# M480_v1 register map
File version: 1.0
Registers are 32-bit, read-write, reset 0x0 unless marked. A register's access mark holds for its fields unless they carry their own. Offsets are from the block's base; [hi:lo] are bit positions; lines under a group give offsets from that group; {n}, {i} and the like mark numbered series; 'fields as' and 'values as' point back to an identical list.

## EPWM0 — EPWM Register Map
Base 0x40058000
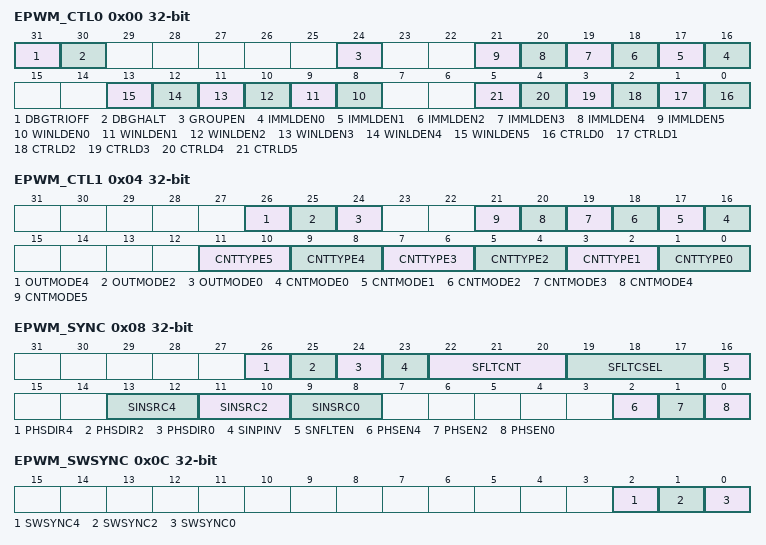
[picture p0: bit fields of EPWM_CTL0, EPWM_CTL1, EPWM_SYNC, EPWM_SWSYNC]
0x00 EPWM_CTL0 — EPWM Control Register 0
  [31] DBGTRIOFF — ICE Debug Mode Acknowledge Disable Bit (Write Protect). EPWM pin will keep output no matter ICE debug mode acknowledged or not. Note: This bit is write protected. Refer to SYS_REGLCTL register.
    0=ICE debug mode acknowledgement effects EPWM output; 1=ICE debug mode acknowledgement disabled
  [30] DBGHALT — ICE Debug Mode Counter Halt (Write Protect). If counter halt is enabled, EPWM all counters will keep current value until exit ICE debug mode. Note: This bit is write protected. Refer to SYS_REGLCTL register.
    0=ICE debug mode counter halt Disabled; 1=ICE debug mode counter halt Enabled
  [24] GROUPEN — Group Function Enable Bit
    0=The output waveform of each EPWM channel are independent; 1=Unify the EPWM_CH2 and EPWM_CH4 to output the same waveform as EPWM_CH0 and unify the EPWM_CH3 and EPWM_CH5 to output the same waveform as EPWM_CH1
  [n+16] IMMLDEN{n} (n=0..5) — Immediately Load Enable Bits. Note: If IMMLDENn is enabled, WINLDENn and CTRLDn will be invalid.
    0=PERIOD will load to PBUF at the end point of each period. CMP will load to CMPBUF at the end point or center point of each period by setting CTRLD bit; 1=PERIOD/CMP will load to PBUF and CMPBUF immediately when software update PERIOD/CMP
  [n+8] WINLDEN{n} (n=0..5) — Window Load Enable Bits
    0=PERIOD will load to PBUF at the end point of each period. CMP will load to CMPBUF at the end point or center point of each period by setting CTRLD bit; 1=PERIOD will load to PBUF at the end point of each period. CMP will load to CMPBUF at the end point of each period when valid reload window is set. The valid reload window is set by software write 1 to EPWM_LOAD register and cleared by hardware after load success
  [n] CTRLD{n} (n=0..5) — Center Re-load. In up-down counter type, PERIOD will load to PBUF at the end point of each period. CMP will load to CMPBUF at the center point of a period.
0x04 EPWM_CTL1 — EPWM Control Register 1
  [26] OUTMODE4 — EPWM Output Mode. Each bit n controls the output mode of corresponding EPWM channel n. Note: When operating in group function, these bits must all set to the same mode.
    0=EPWM independent mode; 1=EPWM complementary mode
  [25] OUTMODE2 — EPWM Output Mode. Each bit n controls the output mode of corresponding EPWM channel n. Note: When operating in group function, these bits must all set to the same mode.
    0=EPWM independent mode; 1=EPWM complementary mode
  [24] OUTMODE0 — EPWM Output Mode. Each bit n controls the output mode of corresponding EPWM channel n. Note: When operating in group function, these bits must all set to the same mode.
    0=EPWM independent mode; 1=EPWM complementary mode
  [n+16] CNTMODE{n} (n=0..5) — EPWM Counter Mode
    0=Auto-reload mode; 1=One-shot mode
  [2n+1:2n] CNTTYPE{n} (n=0..5) — EPWM Counter Behavior Type
    0=Up counter type (supported in capture mode); 1=Down count type (supported in capture mode); 2=Up-down counter type
0x08 EPWM_SYNC — EPWM Synchronization Register
  [26] PHSDIR4 — EPWM Phase Direction Control
    0=Control EPWM counter count decrement after synchronizing; 1=Control EPWM counter count increment after synchronizing
  [25] PHSDIR2 — EPWM Phase Direction Control
    values as PHSDIR4
  [24] PHSDIR0 — EPWM Phase Direction Control
    values as PHSDIR4
  [23] SINPINV — SYNC Input Pin Inverse
    0=The state of pin SYNC is passed to the negative edge detector; 1=The inversed state of pin SYNC is passed to the negative edge detector
  [22:20] SFLTCNT — SYNC Edge Detector Filter Count. The register bits control the counter number of edge detector.
  [19:17] SFLTCSEL — SYNC Edge Detector Filter Clock Selection
    0=Filter clock = HCLK; 1=Filter clock = HCLK/2; 2=Filter clock = HCLK/4; 3=Filter clock = HCLK/8; 4=Filter clock = HCLK/16; 5=Filter clock = HCLK/32; 6=Filter clock = HCLK/64; 7=Filter clock = HCLK/128
  [16] SNFLTEN — EPWM0_SYNC_IN Noise Filter Enable Bits
    0=Noise filter of input pin EPWM0_SYNC_IN Disabled; 1=Noise filter of input pin EPWM0_SYNC_IN Enabled
  [13:12] SINSRC4 — EPWM0_SYNC_IN Source Selection
    0=Synchronize source from SYNC_IN or SWSYNC; 1=Counter equal to 0; 2=Counter equal to EPWM_CMPDATm, m denotes 1, 3, 5; 3=SYNC_OUT will not be generated
  [11:10] SINSRC2 — EPWM0_SYNC_IN Source Selection
    values as SINSRC4
  [9:8] SINSRC0 — EPWM0_SYNC_IN Source Selection
    values as SINSRC4
  [2] PHSEN4 — SYNC Phase Enable Bits
    0=EPWM counter disable to load PHS value; 1=EPWM counter enable to load PHS value
  [1] PHSEN2 — SYNC Phase Enable Bits
    values as PHSEN4
  [0] PHSEN0 — SYNC Phase Enable Bits
    values as PHSEN4
0x0C EPWM_SWSYNC — EPWM Software Control Synchronization Register
  [2] SWSYNC4 — Software SYNC Function. When SINSRCn (EPWM_SYNC[13:8]) is selected to 0, SYNC_OUT source comes from SYNC_IN or this bit.
  [1] SWSYNC2 — Software SYNC Function. When SINSRCn (EPWM_SYNC[13:8]) is selected to 0, SYNC_OUT source comes from SYNC_IN or this bit.
  [0] SWSYNC0 — Software SYNC Function. When SINSRCn (EPWM_SYNC[13:8]) is selected to 0, SYNC_OUT source comes from SYNC_IN or this bit.
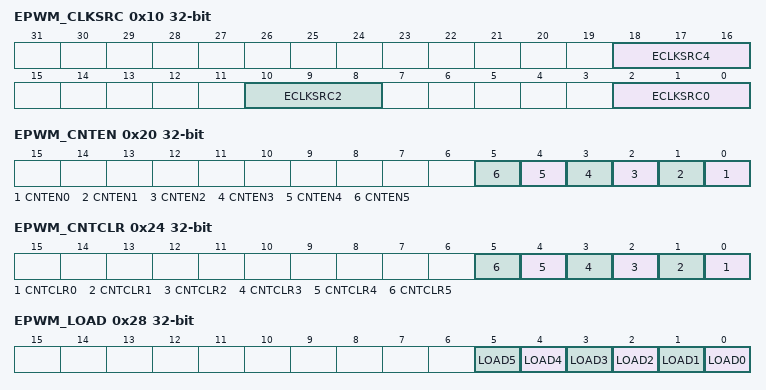
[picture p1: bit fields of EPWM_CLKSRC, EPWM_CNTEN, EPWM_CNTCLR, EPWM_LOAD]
0x10 EPWM_CLKSRC — EPWM Clock Source Register
  [all] fields
    0=EPWMx_CLK, x denotes 0 or 1; {v}=TIMER{v-1} overflow (v=1..4)
  [18:16] ECLKSRC4 — EPWM_CH45 External Clock Source Select
  [10:8] ECLKSRC2 — EPWM_CH23 External Clock Source Select
  [2:0] ECLKSRC0 — EPWM_CH01 External Clock Source Select
0x14 EPWM_CLKPSC0_1 — EPWM Clock Prescale Register 0/1
  [11:0] CLKPSC — EPWM Counter Clock Prescale. The clock of EPWM counter is decided by clock prescaler. Each EPWM pair share one EPWM counter clock prescaler. The clock of EPWM counter is divided by (CLKPSC+ 1).
0x18 EPWM_CLKPSC2_3 — EPWM Clock Prescale Register 2/3
  fields as EPWM_CLKPSC0_1
0x1C EPWM_CLKPSC4_5 — EPWM Clock Prescale Register 4/5
  fields as EPWM_CLKPSC0_1
0x20 EPWM_CNTEN — EPWM Counter Enable Register
  [all] fields
    0=EPWM Counter and clock prescaler stop running; 1=EPWM Counter and clock prescaler start running
  [n] CNTEN{n} (n=0..5) — EPWM Counter Enable Bits
0x24 EPWM_CNTCLR — EPWM Clear Counter Register
  [all] fields
    0=No effect; 1=Clear 16-bit EPWM counter to 0000H
  [n] CNTCLR{n} (n=0..5) — Clear EPWM Counter Control Bit. It is automatically cleared by hardware. Each bit n controls the corresponding EPWM channel n.
0x28 EPWM_LOAD
  [all] fields
    0=No effect. No load window is set; 1=Set load window of window loading mode. Load window is set
  [n] LOAD{n} (n=0..5) — Re-load EPWM Comparator Register (EPWM_CMPDATn) Control Bit. This bit is software write, hardware clear when current EPWM period end. Write Operation:
{0x30+4i} EPWM_PERIOD{i} (i=0..5) — EPWM Period Register {i}
  [15:0] PERIOD — EPWM Period Register. Up-Count mode: In this mode, EPWM counter counts from 0 to PERIOD, and restarts from 0.
{0x50+4i} EPWM_CMPDAT{i} (i=0..5) — EPWM Comparator Register {i}
  [15:0] CMP — EPWM Comparator Register. CMP is used to compare with CNT (EPWM_CNTn[15:0]) bits to generate EPWM waveform, interrupt and trigger EADC/DAC. In complementary mode, EPWM_CMPDAT0, EPWM_CMPDAT 2, EPWM_CMPDAT4 denote as first compared point, and EPWM_CMPDAT1, EPWM_CMPDAT3, EPWM_CMPDAT5 denote as second compared point for the corresponding 3 complementary pairs EPWM_CH0 and EPWM_CH1, EPWM_CH2 and EPWM_CH3, EPWM_CH4 and EPWM_CH5.
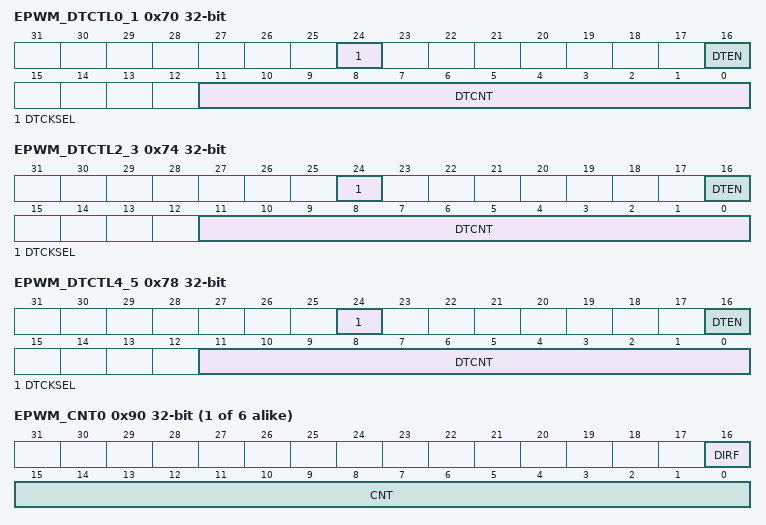
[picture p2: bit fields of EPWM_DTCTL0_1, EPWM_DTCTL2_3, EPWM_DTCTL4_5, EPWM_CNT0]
0x70 EPWM_DTCTL0_1 — EPWM Dead-time Control Register 0/1
  [24] DTCKSEL — Dead-time Clock Select (Write Protect). Note: This bit is write protected. Refer to REGWRPROT register.
    0=Dead-time clock source from EPWM_CLK; 1=Dead-time clock source from prescaler output
  [16] DTEN — Enable Dead-time Insertion for EPWM Pair (EPWM_CH0, EPWM_CH1) (EPWM_CH2, EPWM_CH3) (EPWM_CH4, EPWM_CH5) (Write Protect). Dead-time insertion is only active when this pair of complementary EPWM is enabled. If dead- time insertion is inactive, the outputs of pin pair are complementary without any delay. Note: This bit is write protected. Refer to SYS_REGLCTL register.
    0=Dead-time insertion Disabled on the pin pair; 1=Dead-time insertion Enabled on the pin pair
  [11:0] DTCNT — Dead-time Counter (Write Protect). The dead-time can be calculated from the following formula: Note: This bit is write protected. Refer to SYS_REGLCTL register.
0x74 EPWM_DTCTL2_3 — EPWM Dead-time Control Register 2/3
  fields as EPWM_DTCTL0_1
0x78 EPWM_DTCTL4_5 — EPWM Dead-time Control Register 4/5
  fields as EPWM_DTCTL0_1
0x80 EPWM_PHS0_1 — EPWM Counter Phase Register 0/1
  [15:0] PHS — EPWM Synchronous Start Phase Bits. PHS determines the EPWM synchronous start phase value. These bits only use in synchronous function.
0x84 EPWM_PHS2_3 — EPWM Counter Phase Register 2/3
  fields as EPWM_PHS0_1
0x88 EPWM_PHS4_5 — EPWM Counter Phase Register 4/5
  fields as EPWM_PHS0_1
{0x90+4i} EPWM_CNT{i} ro (i=0..5) — EPWM Counter Register {i}
  [16] DIRF — EPWM Direction Indicator Flag (Read Only)
    0=Counter is counting down; 1=Counter is counting up
  [15:0] CNT — EPWM Data Register (Read Only). User can monitor CNT to know the current value in 16-bit period counter.
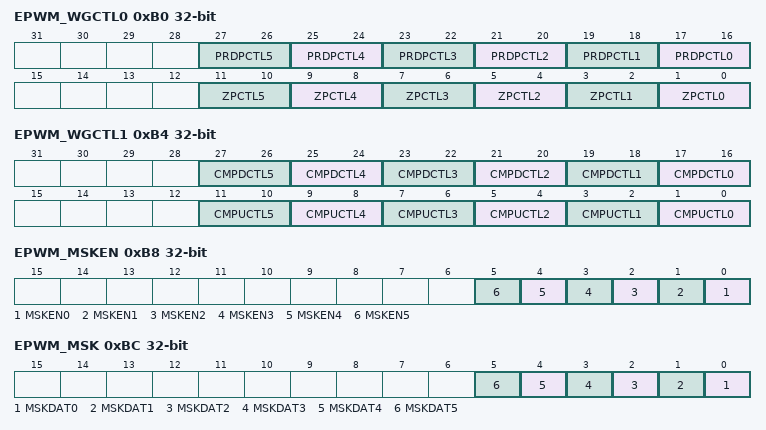
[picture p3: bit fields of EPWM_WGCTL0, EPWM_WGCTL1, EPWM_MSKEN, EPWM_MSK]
0xB0 EPWM_WGCTL0 — EPWM Generation Register 0
  [2n+17:2n+16] PRDPCTL{n} (n=0..5) — EPWM Period (Center) Point Control. EPWM can control output level when EPWM counter counts to (PERIODn+1). Note: This bit is center point control when EPWM counter operating in up-down counter type.
    0=Do nothing; 1=EPWM period (center) point output Low; 2=EPWM period (center) point output High; 3=EPWM period (center) point output Toggle
  [2n+1:2n] ZPCTL{n} (n=0..5) — EPWM Zero Point Control. EPWM can control output level when EPWM counter counts to 0.
    0=Do nothing; 1=EPWM zero point output Low; 2=EPWM zero point output High; 3=EPWM zero point output Toggle
0xB4 EPWM_WGCTL1 — EPWM Generation Register 1
  [2n+17:2n+16] CMPDCTL{n} (n=0..5) — EPWM Compare Down Point Control. EPWM can control output level when EPWM counter counts down to CMP. Note: In complementary mode, CMPDCTL1, 3, 5 is used as another CMPDCTL for channel 0, 2, 4.
    0=Do nothing; 1=EPWM compare down point output Low; 2=EPWM compare down point output High; 3=EPWM compare down point output Toggle
  [2n+1:2n] CMPUCTL{n} (n=0..5) — EPWM Compare Up Point Control. EPWM can control output level when EPWM counter counts up to CMP. Note: In complementary mode, CMPUCTL1, 3, 5 is used as another CMPUCTL for channel 0, 2, 4.
    0=Do nothing; 1=EPWM compare up point output Low; 2=EPWM compare up point output High; 3=EPWM compare up point output Toggle
0xB8 EPWM_MSKEN — EPWM Mask Enable Register
  [all] fields
    0=EPWM output signal is non-masked; 1=EPWM output signal is masked and output MSKDATn data
  [n] MSKEN{n} (n=0..5) — EPWM Mask Enable Bits. The EPWM output signal will be masked when this bit is enabled. The corresponding EPWM channel n will output MSKDATn (EPWM_MSK[5:0]) data.
0xBC EPWM_MSK — EPWM Mask Data Register
  [all] fields
    0=Output logic low to EPWM channel n; 1=Output logic high to EPWM channel n
  [n] MSKDAT{n} (n=0..5) — EPWM Mask Data Bit. This data bit control the state of EPWMn output pin, if corresponding mask function is enabled.
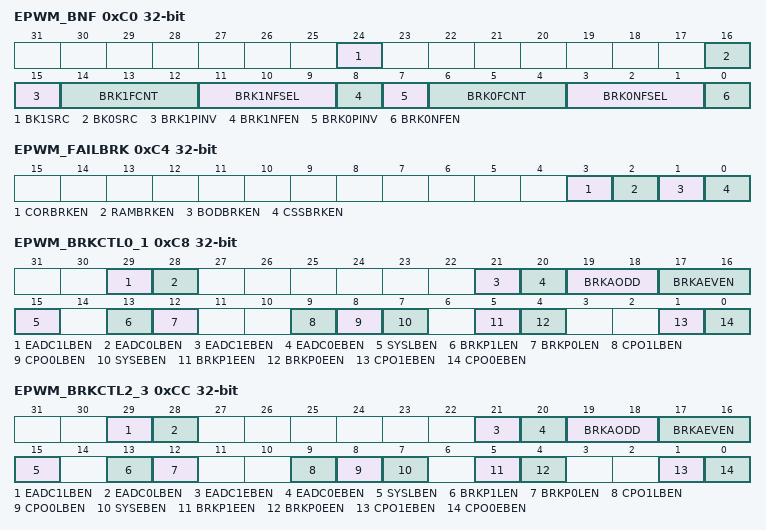
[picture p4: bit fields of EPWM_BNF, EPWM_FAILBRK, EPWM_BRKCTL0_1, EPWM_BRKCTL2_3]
0xC0 EPWM_BNF — EPWM Brake Noise Filter Register
  [24] BK1SRC — Brake 1 Pin Source Select. For EPWM0 setting:
    0=Brake 1 pin source come from EPWM0_BRAKE1. Brake 1 pin source come from EPWM1_BRAKE1; 1=Brake 1 pin source come from EPWM1_BRAKE1. Brake 1 pin source come from EPWM0_BRAKE1
  [16] BK0SRC — Brake 0 Pin Source Select. For EPWM0 setting:
    0=Brake 0 pin source come from EPWM0_BRAKE0. Brake 0 pin source come from EPWM1_BRAKE0; 1=Brake 0 pin source come from EPWM1_BRAKE0. Brake 0 pin source come from EPWM0_BRAKE0
  [15] BRK1PINV — Brake 1 Pin Inverse
    0=brake pin event will be detected if EPWMx_BRAKE1 pin status transfer from low to high in edge-detect, or pin status is high in level-detect; 1=brake pin event will be detected if EPWMx_BRAKE1 pin status transfer from high to low in edge-detect, or pin status is low in level-detect
  [14:12] BRK1FCNT — Brake 1 Edge Detector Filter Count. The register bits control the Brake1 filter counter to count from 0 to BRK1FCNT.
  [11:9] BRK1NFSEL — Brake 1 Edge Detector Filter Clock Selection
    values as EPWM_SYNC.SFLTCSEL
  [8] BRK1NFEN — EPWM Brake 1 Noise Filter Enable Bit
    0=Noise filter of EPWM Brake 1 Disabled; 1=Noise filter of EPWM Brake 1 Enabled
  [7] BRK0PINV — Brake 0 Pin Inverse
    0=brake pin event will be detected if EPWMx_BRAKE0 pin status transfer from low to high in edge-detect, or pin status is high in level-detect; 1=brake pin event will be detected if EPWMx_BRAKE0 pin status transfer from high to low in edge-detect, or pin status is low in level-detect
  [6:4] BRK0FCNT — Brake 0 Edge Detector Filter Count. The register bits control the Brake0 filter counter to count from 0 to BRK0FCNT.
  [3:1] BRK0NFSEL — Brake 0 Edge Detector Filter Clock Selection
    values as EPWM_SYNC.SFLTCSEL
  [0] BRK0NFEN — EPWM Brake 0 Noise Filter Enable Bit
    0=Noise filter of EPWM Brake 0 Disabled; 1=Noise filter of EPWM Brake 0 Enabled
0xC4 EPWM_FAILBRK — EPWM System Fail Brake Control Register
  [3] CORBRKEN — Core Lockup Detection Trigger EPWM Brake Function 0 Enable Bit
    0=Brake Function triggered by Core lockup detection Disabled; 1=Brake Function triggered by Core lockup detection Enabled
  [2] RAMBRKEN — SRAM Parity Error Detection Trigger EPWM Brake Function 0 Enable Bit
    0=Brake Function triggered by SRAM parity error detection Disabled; 1=Brake Function triggered by SRAM parity error detection Enabled
  [1] BODBRKEN — Brown-out Detection Trigger EPWM Brake Function 0 Enable Bit
    0=Brake Function triggered by BOD Disabled; 1=Brake Function triggered by BOD Enabled
  [0] CSSBRKEN — Clock Security System Detection Trigger EPWM Brake Function 0 Enable Bit
    0=Brake Function triggered by CSS detection Disabled; 1=Brake Function triggered by CSS detection Enabled
0xC8 EPWM_BRKCTL0_1 — EPWM Brake Edge Detect Control Register 0/1
  [29] EADC1LBEN — Enable EADC1 Result Monitor (EADC1RM) As Level-detect Brake Source (Write Protect). Note: This bit is write protected. Refer to SYS_REGLCTL register.
    0=EADC1RM as level-detect brake source Disabled; 1=EADC1RM as level-detect brake source Enabled
  [28] EADC0LBEN — Enable EADC0 Result Monitor (EADC0RM) As Level-detect Brake Source (Write Protect). Note: This bit is write protected. Refer to SYS_REGLCTL register.
    0=EADC0RM as level-detect brake source Disabled; 1=EADC0RM as level-detect brake source Enabled
  [21] EADC1EBEN — Enable EADC1 Result Monitor (EADC1RM) As Edge-detect Brake Source (Write Protect). Note: This bit is write protected. Refer to SYS_REGLCTL register.
    0=EADC1RM as edge-detect brake source Disabled; 1=EADC1RM as edge-detect brake source Enabled
  [20] EADC0EBEN — Enable EADC0 Result Monitor (EADC0RM) As Edge-detect Brake Source (Write Protect). Note: This bit is write protected. Refer to SYS_REGLCTL register.
    0=EADC0RM as edge-detect brake source Disabled; 1=EADC0RM as edge-detect brake source Enabled
  [19:18] BRKAODD — EPWM Brake Action Select for Odd Channel (Write Protect). Note: This bit is write protected. Refer to SYS_REGLCTL register.
    0=EPWMx brake event will not affect odd channels output; 1=EPWM odd channel output tri-state when EPWMx brake event happened; 2=EPWM odd channel output low level when EPWMx brake event happened; 3=EPWM odd channel output high level when EPWMx brake event happened
  [17:16] BRKAEVEN — EPWM Brake Action Select for Even Channel (Write Protect). Note: This bit is write protected. Refer to SYS_REGLCTL register.
    0=EPWMx brake event will not affect even channels output; 1=EPWM even channel output tri-state when EPWMx brake event happened; 2=EPWM even channel output low level when EPWMx brake event happened; 3=EPWM even channel output high level when EPWMx brake event happened
  [15] SYSLBEN — Enable System Fail As Level-detect Brake Source (Write Protect). Note: This bit is write protected. Refer to SYS_REGLCTL register.
    0=System Fail condition as level-detect brake source Disabled; 1=System Fail condition as level-detect brake source Enabled
  [13] BRKP1LEN — Enable BKP1 Pin As Level-detect Brake Source (Write Protect). Note: This bit is write protected. Refer to SYS_REGLCTL register.
    0=EPWMx_BRAKE1 pin as level-detect brake source Disabled; 1=EPWMx_BRAKE1 pin as level-detect brake source Enabled
  [12] BRKP0LEN — Enable BKP0 Pin As Level-detect Brake Source (Write Protect). Note: This bit is write protected. Refer to SYS_REGLCTL register.
    0=EPWMx_BRAKE0 pin as level-detect brake source Disabled; 1=EPWMx_BRAKE0 pin as level-detect brake source Enabled
  [9] CPO1LBEN — Enable ACMP1_O Digital Output As Level-detect Brake Source (Write Protect). Note: This bit is write protected. Refer to SYS_REGLCTL register.
    0=ACMP1_O as level-detect brake source Disabled; 1=ACMP1_O as level-detect brake source Enabled
  [8] CPO0LBEN — Enable ACMP0_O Digital Output As Level-detect Brake Source (Write Protect). Note: This bit is write protected. Refer to SYS_REGLCTL register.
    0=ACMP0_O as level-detect brake source Disabled; 1=ACMP0_O as level-detect brake source Enabled
  [7] SYSEBEN — Enable System Fail As Edge-detect Brake Source (Write Protect). Note: This bit is write protected. Refer to SYS_REGLCTL register.
    0=System Fail condition as edge-detect brake source Disabled; 1=System Fail condition as edge-detect brake source Enabled
  [5] BRKP1EEN — Enable EPWMx_BRAKE1 Pin As Edge-detect Brake Source (Write Protect). Note: This bit is write protected. Refer to SYS_REGLCTL register.
    0=EPWMx_BRAKE1 pin as edge-detect brake source Disabled; 1=EPWMx_BRAKE1 pin as edge-detect brake source Enabled
  [4] BRKP0EEN — Enable EPWMx_BRAKE0 Pin As Edge-detect Brake Source (Write Protect). Note: This bit is write protected. Refer to SYS_REGLCTL register.
    0=EPWMx_BRAKE0 pin as edge-detect brake source Disabled; 1=EPWMx_BRAKE0 pin as edge-detect brake source Enabled
  [1] CPO1EBEN — Enable ACMP1_O Digital Output As Edge-detect Brake Source (Write Protect). Note: This bit is write protected. Refer to SYS_REGLCTL register.
    0=ACMP1_O as edge-detect brake source Disabled; 1=ACMP1_O as edge-detect brake source Enabled
  [0] CPO0EBEN — Enable ACMP0_O Digital Output As Edge-detect Brake Source (Write Protect). Note: This bit is write protected. Refer to SYS_REGLCTL register.
    0=ACMP0_O as edge-detect brake source Disabled; 1=ACMP0_O as edge-detect brake source Enabled
0xCC EPWM_BRKCTL2_3 — EPWM Brake Edge Detect Control Register 2/3
  fields as EPWM_BRKCTL0_1
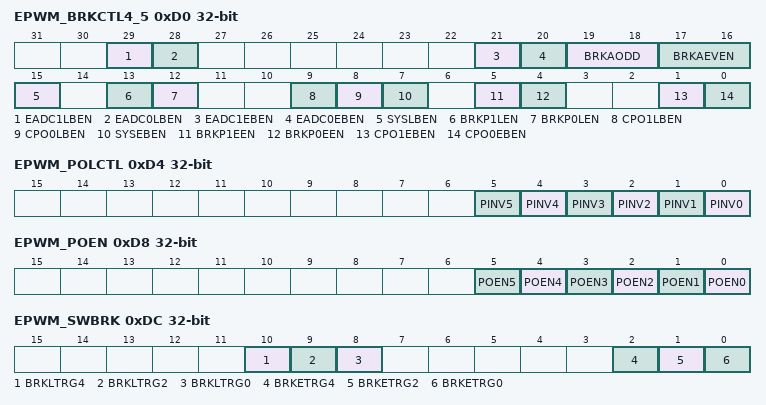
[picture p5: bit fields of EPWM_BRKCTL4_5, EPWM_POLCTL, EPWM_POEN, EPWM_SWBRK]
0xD0 EPWM_BRKCTL4_5 — EPWM Brake Edge Detect Control Register 4/5
  fields as EPWM_BRKCTL0_1
0xD4 EPWM_POLCTL — EPWM Pin Polar Inverse Register
  [all] fields
    0=EPWMx_CHn output pin polar inverse Disabled; 1=EPWMx_CHn output pin polar inverse Enabled
  [n] PINV{n} (n=0..5) — EPWM PIN Polar Inverse Control. The register controls polarity state of EPWMx_CHn output pin.
0xD8 EPWM_POEN — EPWM Output Enable Register
  [all] fields
    0=EPWMx_CHn pin at tri-state; 1=EPWMx_CHn pin in output mode
  [n] POEN{n} (n=0..5) — EPWM Pin Output Enable Bits
0xDC EPWM_SWBRK wo — EPWM Software Brake Control Register
  [10] BRKLTRG4 — EPWM Level Brake Software Trigger (Write Only) (Write Protect). Write 1 to this bit will trigger level brake, and set BRKLIFn to 1 in EPWM_INTSTS1 register. Note: This bit is write protected. Refer to SYS_REGLCTL register.
  [9] BRKLTRG2 — EPWM Level Brake Software Trigger (Write Only) (Write Protect). Write 1 to this bit will trigger level brake, and set BRKLIFn to 1 in EPWM_INTSTS1 register. Note: This bit is write protected. Refer to SYS_REGLCTL register.
  [8] BRKLTRG0 — EPWM Level Brake Software Trigger (Write Only) (Write Protect). Write 1 to this bit will trigger level brake, and set BRKLIFn to 1 in EPWM_INTSTS1 register. Note: This bit is write protected. Refer to SYS_REGLCTL register.
  [2] BRKETRG4 — EPWM Edge Brake Software Trigger (Write Only) (Write Protect). Write 1 to this bit will trigger edge brake, and set BRKEIFn to 1 in EPWM_INTSTS1 register. Note: This bit is write protected. Refer to SYS_REGLCTL register.
  [1] BRKETRG2 — EPWM Edge Brake Software Trigger (Write Only) (Write Protect). Write 1 to this bit will trigger edge brake, and set BRKEIFn to 1 in EPWM_INTSTS1 register. Note: This bit is write protected. Refer to SYS_REGLCTL register.
  [0] BRKETRG0 — EPWM Edge Brake Software Trigger (Write Only) (Write Protect). Write 1 to this bit will trigger edge brake, and set BRKEIFn to 1 in EPWM_INTSTS1 register. Note: This bit is write protected. Refer to SYS_REGLCTL register.
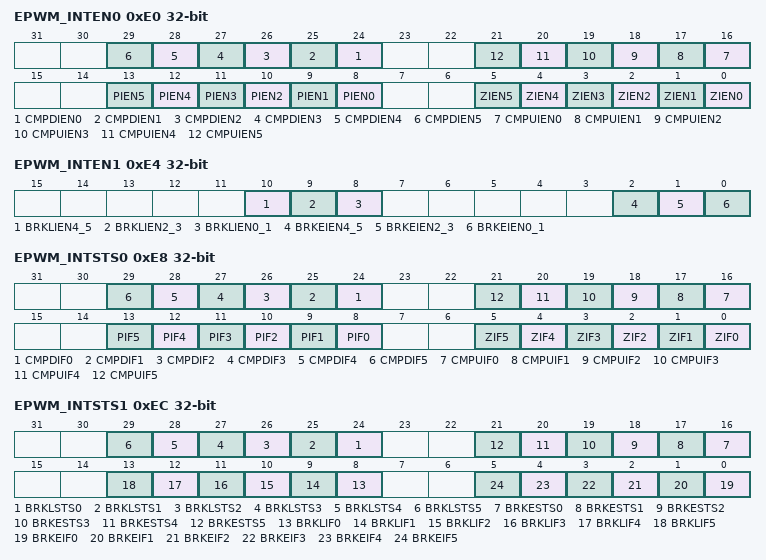
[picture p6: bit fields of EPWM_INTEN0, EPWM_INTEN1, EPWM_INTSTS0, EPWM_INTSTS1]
0xE0 EPWM_INTEN0 — EPWM Interrupt Enable Register 0
  [n+24] CMPDIEN{n} (n=0..5) — EPWM Compare Down Count Interrupt Enable Bits. Note: In complementary mode, CMPDIEN1, 3, 5 is used as another CMPDIEN for channel 0, 2, 4.
    0=Compare down count interrupt Disabled; 1=Compare down count interrupt Enabled
  [n+16] CMPUIEN{n} (n=0..5) — EPWM Compare Up Count Interrupt Enable Bits. Note: In complementary mode, CMPUIEN1, 3, 5 is used as another CMPUIEN for channel 0, 2, 4.
    0=Compare up count interrupt Disabled; 1=Compare up count interrupt Enabled
  [n+8] PIEN{n} (n=0..5) — EPWM Period Point Interrupt Enable Bits. Note1: When up-down counter type period point means center point. Note2: Odd channels will read always 0 at complementary mode.
    0=Period point interrupt Disabled; 1=Period point interrupt Enabled
  [n] ZIEN{n} (n=0..5) — EPWM Zero Point Interrupt Enable Bits. Note: Odd channels will read always 0 at complementary mode.
    0=Zero point interrupt Disabled; 1=Zero point interrupt Enabled
0xE4 EPWM_INTEN1 — EPWM Interrupt Enable Register 1
  [10] BRKLIEN4_5 — EPWM Level-detect Brake Interrupt Enable for Channel4/5 (Write Protect). Note: This bit is write protected. Refer to SYS_REGLCTL register.
    0=Level-detect Brake interrupt for channel4/5 Disabled; 1=Level-detect Brake interrupt for channel4/5 Enabled
  [9] BRKLIEN2_3 — EPWM Level-detect Brake Interrupt Enable for Channel2/3 (Write Protect). Note: This bit is write protected. Refer to SYS_REGLCTL register.
    0=Level-detect Brake interrupt for channel2/3 Disabled; 1=Level-detect Brake interrupt for channel2/3 Enabled
  [8] BRKLIEN0_1 — EPWM Level-detect Brake Interrupt Enable for Channel0/1 (Write Protect). Note: This bit is write protected. Refer to SYS_REGLCTL register.
    0=Level-detect Brake interrupt for channel0/1 Disabled; 1=Level-detect Brake interrupt for channel0/1 Enabled
  [2] BRKEIEN4_5 — EPWM Edge-detect Brake Interrupt Enable for Channel4/5 (Write Protect). Note: This bit is write protected. Refer to SYS_REGLCTL register.
    0=Edge-detect Brake interrupt for channel4/5 Disabled; 1=Edge-detect Brake interrupt for channel4/5 Enabled
  [1] BRKEIEN2_3 — EPWM Edge-detect Brake Interrupt Enable for Channel2/3 (Write Protect). Note: This bit is write protected. Refer to SYS_REGLCTL register.
    0=Edge-detect Brake interrupt for channel2/3 Disabled; 1=Edge-detect Brake interrupt for channel2/3 Enabled
  [0] BRKEIEN0_1 — EPWM Edge-detect Brake Interrupt Enable for Channel0/1 (Write Protect). Note: This bit is write protected. Refer to SYS_REGLCTL register.
    0=Edge-detect Brake interrupt for channel0/1 Disabled; 1=Edge-detect Brake interrupt for channel0/1 Enabled
0xE8 EPWM_INTSTS0 — EPWM Interrupt Flag Register 0
  [n+24] CMPDIF{n} (n=0..5) — EPWM Compare Down Count Interrupt Flag. Flag is set by hardware when EPWM counter down count and reaches EPWM_CMPDATn, software can clear this bit by writing 1 to it. Note: In complementary mode, CMPDIF1, 3, 5 is used as another CMPDIF for channel 0, 2, 4.
  [n+16] CMPUIF{n} (n=0..5) — EPWM Compare Up Count Interrupt Flag. Flag is set by hardware when EPWM counter up count and reaches EPWM_CMPDATn, software can clear this bit by writing 1 to it. Note: In complementary mode, CMPUIF1, 3, 5 is used as another CMPUIF for channel 0, 2, 4.
  [n+8] PIF{n} (n=0..5) — EPWM Period Point Interrupt Flag. This bit is set by hardware when EPWM counter reaches EPWM_PERIODn. Note: This bit can be cleared to 0 by software writing 1.
  [n] ZIF{n} (n=0..5) — EPWM Zero Point Interrupt Flag. This bit is set by hardware when EPWM counter reaches 0. Note: This bit can be cleared to 0 by software writing 1
0xEC EPWM_INTSTS1 — EPWM Interrupt Flag Register 1
  [n+24] BRKLSTS{n} ro (n=0..5) — EPWM Channel N Level-detect Brake Status (Read Only). Note: This bit is read only and auto cleared by hardware. When enabled brake source return to high level, EPWM will release brake state until current EPWM period finished. The EPWM waveform will start output from next full EPWM period.
    0=EPWM channel n level-detect brake state is released; 1=When EPWM channel n level-detect brake detects a falling edge of any enabled brake source; this flag will be set to indicate the EPWM channel n at brake state
  [n+16] BRKESTS{n} ro (n=0..5) — EPWM Channel N Edge-detect Brake Status (Read Only). Note: This bit is read only and auto cleared by hardware. When edge-detect brake interrupt flag is cleared, EPWM will release brake state until current EPWM period finished. The EPWM waveform will start output from next full EPWM period.
    0=EPWM channel n edge-detect brake state is released; 1=When EPWM channel n edge-detect brake detects a falling edge of any enabled brake source; this flag will be set to indicate the EPWM channel n at brake state
  [n+8] BRKLIF{n} (n=0..5) — EPWM Channel N Level-detect Brake Interrupt Flag (Write Protect). Note: This bit is write protected. Refer to SYS_REGLCTL register.
    0=EPWM channel n level-detect brake event do not happened; 1=When EPWM channel n level-detect brake event happened, this bit is set to 1, writing 1 to clear
  [n] BRKEIF{n} (n=0..5) — EPWM Channel N Edge-detect Brake Interrupt Flag (Write Protect). Note: This bit is write protected. Refer to SYS_REGLCTL register.
    0=EPWM channel n edge-detect brake event do not happened; 1=When EPWM channel n edge-detect brake event happened, this bit is set to 1, writing 1 to clear
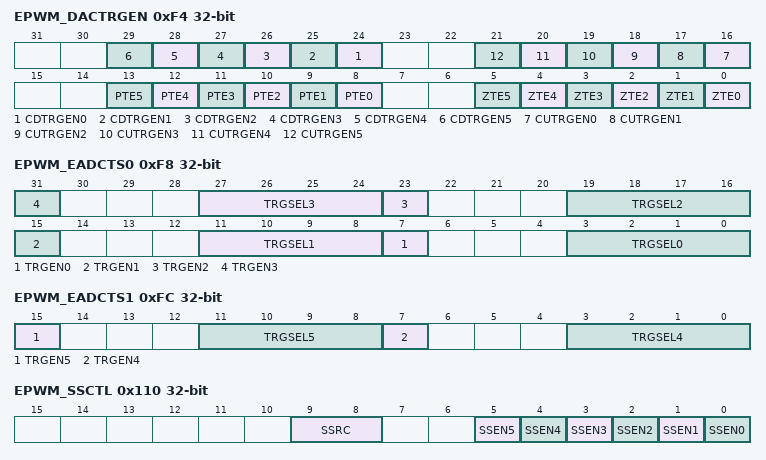
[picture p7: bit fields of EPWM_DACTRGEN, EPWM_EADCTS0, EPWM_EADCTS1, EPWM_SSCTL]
0xF4 EPWM_DACTRGEN — EPWM Trigger DAC Enable Register
  [n+24] CDTRGEN{n} (n=0..5) — EPWM Compare Down Count Point Trigger DAC Enable Bits. EPWM can trigger DAC to start action when EPWM counter down count to CMP if this bit is set to1. Note1: This bit should keep at 0 when EPWM counter operating in up counter type. Note2: In complementary mode, CDTRGEN1, 3, 5 is used as another CDTRGEN for channel 0, 2, 4.
    0=EPWM Compare Down count point trigger DAC function Disabled; 1=EPWM Compare Down count point trigger DAC function Enabled
  [n+16] CUTRGEN{n} (n=0..5) — EPWM Compare Up Count Point Trigger DAC Enable Bits. EPWM can trigger DAC to start action when EPWM counter counts up to CMP if this bit is set to1. Note1: This bit should keep at 0 when EPWM counter operating in down counter type. Note2: In complementary mode, CUTRGEN1, 3, 5 is used as another CUTRGEN for channel 0, 2, 4.
    0=EPWM Compare Up point trigger DAC function Disabled; 1=EPWM Compare Up point trigger DAC function Enabled
  [n+8] PTE{n} (n=0..5) — EPWM Period Point Trigger DAC Enable Bits. EPWM can trigger DAC to start action when EPWM counter counts up to (PERIODn+1) if this bit is set to1.
    0=EPWM period point trigger DAC function Disabled; 1=EPWM period point trigger DAC function Enabled
  [n] ZTE{n} (n=0..5) — EPWM Zero Point Trigger DAC Enable Bits. EPWM can trigger EADC/DAC/DMA to start action when EPWM counter down count to zero if this bit is set to1.
    values as PTE0
0xF8 EPWM_EADCTS0 — EPWM Trigger EADC Source Select Register 0
  [8n+7] TRGEN{n} (n=0..3) — EPWM_CH{n} Trigger EADC Enable Bit
    0=EPWM_CH{n} Trigger EADC function Disabled; 1=EPWM_CH{n} Trigger EADC function Enabled
  [27:24] TRGSEL3 — EPWM_CH3 Trigger EADC Source Select
    0=EPWM_CH2 zero point; 1=EPWM_CH2 period point; 2=EPWM_CH2 zero or period point; 3=EPWM_CH2 up-count compared point; 4=EPWM_CH2 down-count compared point; 5=EPWM_CH3 zero point; 6=EPWM_CH3 period point; 7=EPWM_CH3 zero or period point; 8=EPWM_CH3 up-count compared point; 9=EPWM_CH3 down-count compared point; 10=EPWM_CH0 up-count free trigger compared point; 11=EPWM_CH0 down-count free trigger compared point; 12=EPWM_CH2 up-count free trigger compared point; 13=EPWM_CH2 down-count free trigger compared point; 14=EPWM_CH4 up-count free trigger compared point; 15=EPWM_CH4 down-count free trigger compared point
  [19:16] TRGSEL2 — EPWM_CH2 Trigger EADC Source Select
    values as TRGSEL3
  [11:8] TRGSEL1 — EPWM_CH1 Trigger EADC Source Select
    0=EPWM_CH0 zero point; 1=EPWM_CH0 period point; 2=EPWM_CH0 zero or period point; 3=EPWM_CH0 up-count compared point; 4=EPWM_CH0 down-count compared point; 5=EPWM_CH1 zero point; 6=EPWM_CH1 period point; 7=EPWM_CH1 zero or period point; 8=EPWM_CH1 up-count compared point; 9=EPWM_CH1 down-count compared point; 10=EPWM_CH0 up-count free trigger compared point; 11=EPWM_CH0 down-count free trigger compared point; 12=EPWM_CH2 up-count free trigger compared point; 13=EPWM_CH2 down-count free trigger compared point; 14=EPWM_CH4 up-count free trigger compared point; 15=EPWM_CH4 down-count free trigger compared point
  [3:0] TRGSEL0 — EPWM_CH0 Trigger EADC Source Select
    values as TRGSEL1
0xFC EPWM_EADCTS1 — EPWM Trigger EADC Source Select Register 1
  [15] TRGEN5 — EPWM_CH5 Trigger EADC Enable Bit
    0=EPWM_CH5 Trigger EADC function Disabled; 1=EPWM_CH5 Trigger EADC function Enabled
  [11:8] TRGSEL5 — EPWM_CH5 Trigger EADC Source Select
    0=EPWM_CH4 zero point; 1=EPWM_CH4 period point; 2=EPWM_CH4 zero or period point; 3=EPWM_CH4 up-count compared point; 4=EPWM_CH4 down-count compared point; 5=EPWM_CH5 zero point; 6=EPWM_CH5 period point; 7=EPWM_CH5 zero or period point; 8=EPWM_CH5 up-count compared point; 9=EPWM_CH5 down-count compared point; 10=EPWM_CH0 up-count free trigger compared point; 11=EPWM_CH0 down-count free trigger compared point; 12=EPWM_CH2 up-count free trigger compared point; 13=EPWM_CH2 down-count free trigger compared point; 14=EPWM_CH4 up-count free trigger compared point; 15=EPWM_CH4 down-count free trigger compared point
  [7] TRGEN4 — EPWM_CH4 Trigger EADC Enable Bit
    0=EPWM_CH4 Trigger EADC function Disabled; 1=EPWM_CH4 Trigger EADC function Enabled
  [3:0] TRGSEL4 — EPWM_CH4 Trigger EADC Source Select
    values as TRGSEL5
0x100 EPWM_FTCMPDAT0_1 — EPWM Free Trigger Compare Register 0/1
  [15:0] FTCMP — EPWM Free Trigger Compare Register
0x104 EPWM_FTCMPDAT2_3 — EPWM Free Trigger Compare Register 2/3
  [15:0] FTCMP — EPWM Free Trigger Compare Register
0x108 EPWM_FTCMPDAT4_5 — EPWM Free Trigger Compare Register 4/5
  [15:0] FTCMP — EPWM Free Trigger Compare Register
0x110 EPWM_SSCTL — EPWM Synchronous Start Control Register
  [9:8] SSRC — EPWM Synchronous Start Source Select Bits
    0=Synchronous start source come from EPWM0; 1=Synchronous start source come from EPWM1; 2=Synchronous start source come from BPWM0; 3=Synchronous start source come from BPWM1
  [n] SSEN{n} (n=0..5) — EPWM Synchronous Start Function Enable Bits. When synchronous start function is enabled, the EPWM counter enable register (EPWM_CNTEN) can be enabled by writing EPWM synchronous start trigger bit (CNTSEN).
    0=EPWM synchronous start function Disabled; 1=EPWM synchronous start function Enabled
0x114 EPWM_SSTRG wo — EPWM Synchronous Start Trigger Register
  [0] CNTSEN — EPWM Counter Synchronous Start Enable (Write Only). PMW counter synchronous enable function is used to make selected EPWM channels (include EPWM0_CHx and EPWM1_CHx) start counting at the same time. Writing this bit to 1 will also set the counter enable bit (CNTENn, n denotes channel 0 to 5) if correlated EPWM channel counter synchronous start function is enabled.
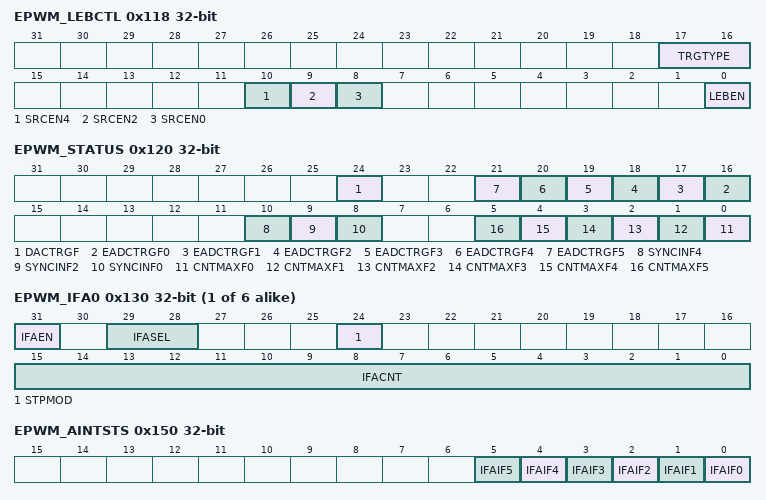
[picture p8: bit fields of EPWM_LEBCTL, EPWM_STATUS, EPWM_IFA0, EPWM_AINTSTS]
0x118 EPWM_LEBCTL — EPWM Leading Edge Blanking Control Register
  [17:16] TRGTYPE — EPWM Leading Edge Blanking Trigger Type
    0=When detect leading edge blanking source rising edge, blanking counter start counting; 1=When detect leading edge blanking source falling edge, blanking counter start counting; 2=When detect leading edge blanking source rising or falling edge, blanking counter start counting
  [10] SRCEN4 — EPWM Leading Edge Blanking Source From EPWM_CH4 Enable Bit
    0=EPWM Leading Edge Blanking Source from EPWM_CH4 Disabled; 1=EPWM Leading Edge Blanking Source from EPWM_CH4 Enabled
  [9] SRCEN2 — EPWM Leading Edge Blanking Source From EPWM_CH2 Enable Bit
    0=EPWM Leading Edge Blanking Source from EPWM_CH2 Disabled; 1=EPWM Leading Edge Blanking Source from EPWM_CH2 Enabled
  [8] SRCEN0 — EPWM Leading Edge Blanking Source From EPWM_CH0 Enable Bit
    0=EPWM Leading Edge Blanking Source from EPWM_CH0 Disabled; 1=EPWM Leading Edge Blanking Source from EPWM_CH0 Enabled
  [0] LEBEN — EPWM Leading Edge Blanking Enable Bit
    0=EPWM Leading Edge Blanking Disabled; 1=EPWM Leading Edge Blanking Enabled
0x11C EPWM_LEBCNT — EPWM Leading Edge Blanking Counter Register
  [8:0] LEBCNT — EPWM Leading Edge Blanking Counter
0x120 EPWM_STATUS
  [24] DACTRGF — DAC Start of Conversion Flag. Note: This bit can be cleared by software writing 1.
    0=No DAC start of conversion trigger event has occurred; 1=A DAC start of conversion trigger event has occurred
  [n+16] EADCTRGF{n} (n=0..5) — EADC Start of Conversion Flag. Note: This bit can be cleared by software writing 1.
    0=No EADC start of conversion trigger event has occurred; 1=An EADC start of conversion trigger event has occurred
  [10] SYNCINF4 — Input Synchronization Latched Flag. Note: This bit can be cleared by software writing 1.
    0=No SYNC_IN event has occurred; 1=A SYNC_IN event has occurred
  [9] SYNCINF2 — Input Synchronization Latched Flag. Note: This bit can be cleared by software writing 1.
    values as SYNCINF4
  [8] SYNCINF0 — Input Synchronization Latched Flag. Note: This bit can be cleared by software writing 1.
    values as SYNCINF4
  [n] CNTMAXF{n} (n=0..5) — Time-base Counter Equal to 0xFFFF Latched Flag. Note: This bit can be cleared by software writing 1.
    0=The time-base counter never reached its maximum value 0xFFFF; 1=The time-base counter reached its maximum value
{0x130+4i} EPWM_IFA{i} (i=0..5) — EPWM Interrupt Flag Accumulator Register {i}
  [31] IFAEN — EPWM_CHn Interrupt Flag Accumulator Enable Bits
    0=EPWM_CHn interrupt flag accumulator Disabled; 1=EPWM_CHn interrupt flag accumulator Enabled
  [29:28] IFASEL — EPWM_CHn Interrupt Flag Accumulator Source Select
    0=EPWM_CHn zero point; 1=EPWM_CHn period in channel n; 2=EPWM_CHn up-count compared point; 3=EPWM_CHn down-count compared point
  [24] STPMOD — EPWM_CHn Accumulator Stop Mode Enable Bits
    0=EPWM_CHn Stop Mode Disable; 1=EPWM_CHn Stop Mode Enable
  [15:0] IFACNT — EPWM_CHn Interrupt Flag Counter. The register sets the count number which defines (IFACNT+1) times of EPWM_CHn period occurs to set bit IFAIFn to request the EPWM period interrupt. EPWM flag will be set in every IFACNT[15:0] times of EPWM period.
0x150 EPWM_AINTSTS — EPWM Accumulator Interrupt Flag Register
  [n] IFAIF{n} (n=0..5) — EPWM_CHn Interrupt Flag Accumulator Interrupt Flag. Flag is set by hardware when condition match IFASEL in EPWM_IFAn register, software can clear this bit by writing 1 to it.
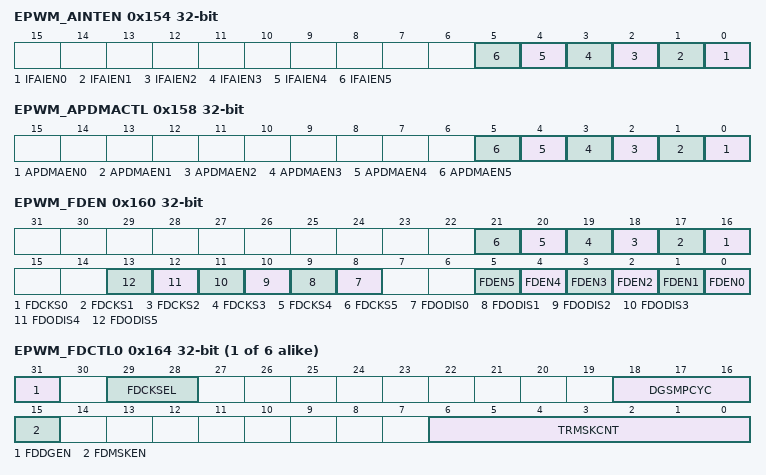
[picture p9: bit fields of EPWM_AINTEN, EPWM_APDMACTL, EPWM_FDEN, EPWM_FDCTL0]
0x154 EPWM_AINTEN — EPWM Accumulator Interrupt Enable Register
  [all] fields
    0=Interrupt Flag accumulator interrupt Disabled; 1=Interrupt Flag accumulator interrupt Enabled
  [n] IFAIEN{n} (n=0..5) — EPWM_CHn Interrupt Flag Accumulator Interrupt Enable Bits
0x158 EPWM_APDMACTL — EPWM Accumulator PDMA Control Register
  [all] fields
    0=Channel n PDMA function Disabled; 1=Channel n PDMA function Enabled for the channel n to trigger PDMA to transfer memory data to register
  [n] APDMAEN{n} (n=0..5) — Channel n Accumulator PDMA Enable Bits
0x160 EPWM_FDEN — EPWM Fault Detect Enable Register
  [n+16] FDCKS{n} (n=0..5) — EPWM Channel n Fault Detect Clock Source Select Bit
    0=EPWMx_CLK, x denotes 0 or 1; 1=EPWMx_CLK divide by prescaler, x denotes 0 or 1
  [n+8] FDODIS{n} (n=0..5) — EPWM Channel n Output Fault Detect Disable Bit
    0=EPWM detect fault and output Enable; 1=EPWM detect fault and output Disable
  [n] FDEN{n} (n=0..5) — EPWM Fault Detect Function Enable Bit
    0=Fault detect function Disable; 1=Fault detect function Enable
{0x164+4i} EPWM_FDCTL{i} (i=0..5) — EPWM Fault Detect Control Register {i}
  [31] FDDGEN — Fault Detect Deglitch Enable Bit
    0=Fault detect deglitch function Disable; 1=Fault detect deglitch function Enable
  [29:28] FDCKSEL — EPWM Channel Fault Detect Clock Select
    0=FLT_CLK/1; 1=FLT_CLK/2; 2=FLT_CLK/4; 3=FLT_CLK/8
  [18:16] DGSMPCYC — Deglitch Sampling Cycle. FDCKS is set to 0: Sampling detect signal each EPWMx_CLK * (2^FDCKSEL) period and detect DGSMPCYC+1 times. FDCKS is set to 1: Sampling detect signal each EPWMx_CLK * CLKPSC * (2^FDCKSEL) period and detect DGSMPCYC+1 times . Note: CLKPSC (EPWM_CLKPSCn_m[11:0]) is 0:
  [15] FDMSKEN — Fault Detect Mask Enable Bit
    0=Fault detect mask function Disable; 1=Fault detect mask function Enable
  [6:0] TRMSKCNT — Transition Mask Counter. The fault detect result will be masked before counter count from 0 to TRMSKCNT. . FDCKS is set to 0: Mask time is EPWMx_CLK * (2^FDCKSEL) * (TRMSKCNT+2). FDCKS is set to 1: Mask time EPWMx_CLK * CLKPSC * (2^FDCKSEL) * (TRMSKCNT+2) . Note: CLKPSC (EPWM_CLKPSCn_m[11:0]) is 0:
0x17C EPWM_FDIEN — EPWM Fault Detect Interrupt Enable Register
  [0] FDIENn — EPWM Channel n Fault Detect Interrupt Enable Bit
    0=EPWM Channel n Fault Detect Interrupt Disable; 1=EPWM Channel n Fault Detect Interrupt Enable
0x180 EPWM_FDSTS — EPWM Fault Detect Interrupt Flag Register
  [5:0] FDIFn — EPWM Channel n Fault Detect Interrupt Flag Bit. Fault Detect Interrupt Flag will be set when EPWM output short. Software can clear this bit by writing 1 to it.
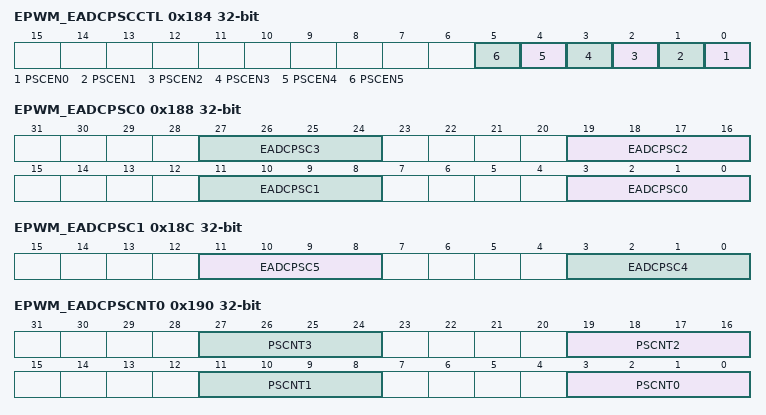
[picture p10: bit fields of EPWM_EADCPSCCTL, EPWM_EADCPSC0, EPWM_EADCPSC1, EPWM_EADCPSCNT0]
0x184 EPWM_EADCPSCCTL — EPWM Trigger EADC Prescale Control Register
  [all] fields
    0=EPWM Trigger EADC Pre-scale Function Disable; 1=EPWM Trigger EADC Pre-scale Function Enable
  [n] PSCEN{n} (n=0..5) — EPWM Trigger EADC Pre-scale Function Enable Bits
0x188 EPWM_EADCPSC0 — EPWM Trigger EADC Prescale Register 0
  [8n+3:8n] EADCPSC{n} (n=0..3) — EPWM Channel {n} Trigger EADC Prescale. The register sets the count number which defines (EADCPSC{n}+1) times of EPWM_CH{n} trigger EADC event occurs to trigger EADC and set trigger EADC flag bit EADCTRGF{n}.
0x18C EPWM_EADCPSC1 — EPWM Trigger EADC Prescale Register 1
  [11:8] EADCPSC5 — EPWM Channel 5 Trigger EADC Prescale. The register sets the count number which defines (EADCPSC5+1) times of EPWM_CH5 trigger EADC event occurs to trigger EADC and set trigger EADC flag bit EADCTRGF5.
  [3:0] EADCPSC4 — EPWM Channel 4 Trigger EADC Prescale. The register sets the count number which defines (EADCPSC4+1) times of EPWM_CH4 trigger EADC event occurs to trigger EADC and set trigger EADC flag bit EADCTRGF4.
0x190 EPWM_EADCPSCNT0 — EPWM Trigger EADC Prescale Counter Register 0
  [8n+3:8n] PSCNT{n} (n=0..3) — EPWM Trigger EADC Prescale Counter {n}. User can monitor PSCNT{n} to know the current value in 4-bit trigger EADC prescale counter. Note1: user can write only when PSCEN{n} is 0. Note2: Write data limitation: PSCNT{n} EADCPSC{n}.
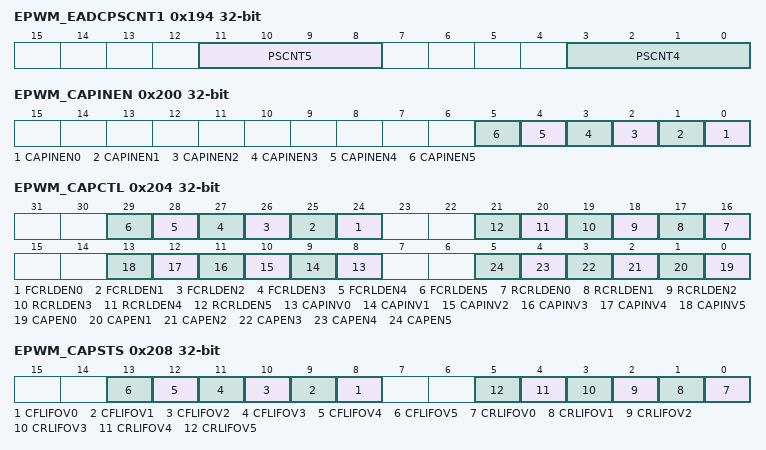
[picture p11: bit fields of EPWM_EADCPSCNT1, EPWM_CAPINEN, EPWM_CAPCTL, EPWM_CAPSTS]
0x194 EPWM_EADCPSCNT1 — EPWM Trigger EADC Prescale Counter Register 1
  [11:8] PSCNT5 — EPWM Trigger EADC Prescale Counter 5. User can monitor PSCNT5 to know the current value in 4-bit trigger EADC prescale counter. Note1: user can write only when PSCEN5 is 0. Note2: Write data limitation: PSCNT5 EADCPSC5.
  [3:0] PSCNT4 — EPWM Trigger EADC Prescale Counter 4. User can monitor PSCNT4 to know the current value in 4-bit trigger EADC prescale counter. Note1: user can write only when PSCEN4 is 0. Note2: Write data limitation: PSCNT4 EADCPSC4.
0x200 EPWM_CAPINEN — EPWM Capture Input Enable Register
  [all] fields
    0=EPWM Channel capture input path Disabled. The input of EPWM channel capture function is always regarded as 0; 1=EPWM Channel capture input path Enabled. The input of EPWM channel capture function comes from correlative multifunction pin
  [n] CAPINEN{n} (n=0..5) — Capture Input Enable Bits
0x204 EPWM_CAPCTL — EPWM Capture Control Register
  [n+24] FCRLDEN{n} (n=0..5) — Falling Capture Reload Enable Bits
    0=Falling capture reload counter Disabled; 1=Falling capture reload counter Enabled
  [n+16] RCRLDEN{n} (n=0..5) — Rising Capture Reload Enable Bits
    0=Rising capture reload counter Disabled; 1=Rising capture reload counter Enabled
  [n+8] CAPINV{n} (n=0..5) — Capture Inverter Enable Bits
    0=Capture source inverter Disabled; 1=Capture source inverter Enabled. Reverse the input signal from GPIO
  [n] CAPEN{n} (n=0..5) — Capture Function Enable Bits
    0=Capture function Disabled. EPWM_RCAPDATn/EPWM_FCAPDATn register will not be updated; 1=Capture function Enabled. Capture latched the EPWM counter value when detected rising or falling edge of input signal and saved to RCAPDAT (Rising latch) and FCAPDAT (Falling latch)
0x208 EPWM_CAPSTS ro — EPWM Capture Status Register
  [n+8] CFLIFOV{n} (n=0..5) — Capture Falling Latch Interrupt Flag Overrun Status (Read Only). This flag indicates if falling latch happened when the corresponding CFLIFn(EPWM_CAPIF[8+n]) is 1. Note: This bit will be cleared automatically when user clear corresponding CFLIFn(EPWM_CAPIF[8+n]).
  [n] CRLIFOV{n} (n=0..5) — Capture Rising Latch Interrupt Flag Overrun Status (Read Only). This flag indicates if rising latch happened when the corresponding CRLIFn(EPWM_CAPIF[n]) is 1. Note: This bit will be cleared automatically when user clear corresponding CRLIFn(EPWM_CAPIF[n]).
{0x20C+8i} EPWM_RCAPDAT{i} ro (i=0..5) — EPWM Rising Capture Data Register {i}
  [15:0] RCAPDAT — EPWM Rising Capture Data Register (Read Only). When rising capture condition happened, the EPWM counter value will be saved in this register.
{0x210+8i} EPWM_FCAPDAT{i} ro (i=0..5) — EPWM Falling Capture Data Register {i}
  [15:0] FCAPDAT — EPWM Falling Capture Data Register (Read Only). When falling capture condition happened, the EPWM counter value will be saved in this register.
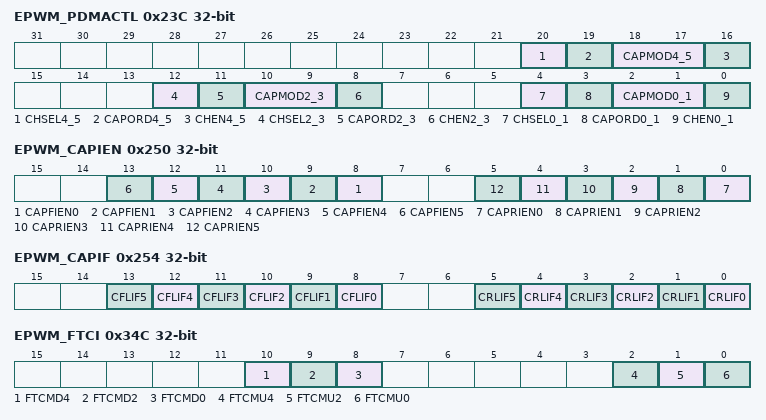
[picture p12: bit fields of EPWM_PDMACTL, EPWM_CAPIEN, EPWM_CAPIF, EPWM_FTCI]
0x23C EPWM_PDMACTL — EPWM PDMA Control Register
  [20] CHSEL4_5 — Select Channel 4/5 to Do PDMA Transfer
    0=Channel4; 1=Channel5
  [19] CAPORD4_5 — Capture Channel 4/5 Rising/Falling Order
    0=EPWM_FCAPDAT4/5 is the first captured data to memory; 1=EPWM_RCAPDAT4/5 is the first captured data to memory
  [18:17] CAPMOD4_5 — Select EPWM_RCAPDAT4/5 or EPWM_FCAPDAT4/5 to Do PDMA Transfer
    1=EPWM_RCAPDAT4/5; 2=EPWM_FCAPDAT4/5; 3=Both EPWM_RCAPDAT4/5 and EPWM_FCAPDAT4/5
  [16] CHEN4_5 — Channel 4/5 PDMA Enable Bit
    0=Channel 4/5 PDMA function Disabled; 1=Channel 4/5 PDMA function Enabled for the channel 4/5 captured data and transfer to memory
  [12] CHSEL2_3 — Select Channel 2/3 to Do PDMA Transfer
    0=Channel2; 1=Channel3
  [11] CAPORD2_3 — Capture Channel 2/3 Rising/Falling Order
    0=EPWM_FCAPDAT2/3 is the first captured data to memory; 1=EPWM_RCAPDAT2/3 is the first captured data to memory
  [10:9] CAPMOD2_3 — Select EPWM_RCAPDAT2/3 or EPWM_FCAODAT2/3 to Do PDMA Transfer
    1=EPWM_RCAPDAT2/3; 2=EPWM_FCAPDAT2/3; 3=Both EPWM_RCAPDAT2/3 and EPWM_FCAPDAT2/3
  [8] CHEN2_3 — Channel 2/3 PDMA Enable Bit
    0=Channel 2/3 PDMA function Disabled; 1=Channel 2/3 PDMA function Enabled for the channel 2/3 captured data and transfer to memory
  [4] CHSEL0_1 — Select Channel 0/1 to Do PDMA Transfer
    0=Channel0; 1=Channel1
  [3] CAPORD0_1 — Capture Channel 0/1 Rising/Falling Order
    0=EPWM_FCAPDAT0/1 is the first captured data to memory; 1=EPWM_RCAPDAT0/1 is the first captured data to memory
  [2:1] CAPMOD0_1 — Select EPWM_RCAPDAT0/1 or EPWM_FCAPDAT0/1 to Do PDMA Transfer
    1=EPWM_RCAPDAT0/1; 2=EPWM_FCAPDAT0/1; 3=Both EPWM_RCAPDAT0/1 and EPWM_FCAPDAT0/1
  [0] CHEN0_1 — Channel 0/1 PDMA Enable Bit
    0=Channel 0/1 PDMA function Disabled; 1=Channel 0/1 PDMA function Enabled for the channel 0/1 captured data and transfer to memory
0x240 EPWM_PDMACAP0_1 ro — EPWM Capture Channel 01 PDMA Register
  [15:0] CAPBUF — EPWM Capture PDMA Register (Read Only). This register is used as a buffer to transfer EPWM capture rising or falling data to memory by PDMA.
0x244 EPWM_PDMACAP2_3 ro — EPWM Capture Channel 23 PDMA Register
  fields as EPWM_PDMACAP0_1
0x248 EPWM_PDMACAP4_5 ro — EPWM Capture Channel 45 PDMA Register
  fields as EPWM_PDMACAP0_1
0x250 EPWM_CAPIEN — EPWM Capture Interrupt Enable Register
  [n+8] CAPFIEN{n} (n=0..5) — EPWM Capture Falling Latch Interrupt Enable Bits
    0=Capture falling edge latch interrupt Disabled; 1=Capture falling edge latch interrupt Enabled
  [n] CAPRIEN{n} (n=0..5) — EPWM Capture Rising Latch Interrupt Enable Bits
    0=Capture rising edge latch interrupt Disabled; 1=Capture rising edge latch interrupt Enabled
0x254 EPWM_CAPIF — EPWM Capture Interrupt Flag Register
  [n+8] CFLIF{n} (n=0..5) — EPWM Capture Falling Latch Interrupt Flag. Note1: When Capture with PDMA operating, EPWM_CAPIF corresponding channel CFLIFn will be cleared by hardware after PDMA transfer data. Note2: This bit is cleared by writing 1 to it.
    0=No capture falling latch condition happened; 1=Capture falling latch condition happened, this flag will be set to high
  [n] CRLIF{n} (n=0..5) — EPWM Capture Rising Latch Interrupt Flag. Note1: When Capture with PDMA operating, EPWM_CAPIF corresponding channel CRLIFn will be cleared by hardware after PDMA transfer data. Note2: This bit is cleared by writing 1 to it.
    0=No capture rising latch condition happened; 1=Capture rising latch condition happened, this flag will be set to high
{0x304+4i} EPWM_PBUF{i} ro (i=0..5) — EPWM PERIOD{i} Buffer
  [15:0] PBUF — EPWM Period Register Buffer (Read Only). Used as PERIOD active register.
{0x31C+4i} EPWM_CMPBUF{i} ro (i=0..5) — EPWM CMPDAT{i} Buffer
  [15:0] CMPBUF — EPWM Comparator Register Buffer (Read Only). Used as CMP active register.
0x334 EPWM_CPSCBUF0_1 ro — EPWM CLKPSC0_1 Buffer
  [11:0] CPSCBUF — EPWM Counter Clock Prescale Buffer. Used as EPWM counter clock pre-scare active register.
0x338 EPWM_CPSCBUF2_3 ro — EPWM CLKPSC2_3 Buffer
  fields as EPWM_CPSCBUF0_1
0x33C EPWM_CPSCBUF4_5 ro — EPWM CLKPSC4_5 Buffer
  fields as EPWM_CPSCBUF0_1
0x340 EPWM_FTCBUF0_1 ro — EPWM FTCMPDAT0_1 Buffer
  [15:0] FTCMPBUF — EPWM FTCMPDAT Buffer (Read Only). Used as FTCMP active buffer.
0x344 EPWM_FTCBUF2_3 ro — EPWM FTCMPDAT2_3 Buffer
  fields as EPWM_FTCBUF0_1
0x348 EPWM_FTCBUF4_5 ro — EPWM FTCMPDAT4_5 Buffer
  fields as EPWM_FTCBUF0_1
0x34C EPWM_FTCI — EPWM FTCMPDAT Indicator Register
  [10] FTCMD4 — EPWM FTCMPDAT Down Indicator. Indicator is set by hardware when EPWM counter down count and reaches EPWM_FTCMPDATn, software can clear this bit by writing 1 to it.
  [9] FTCMD2 — EPWM FTCMPDAT Down Indicator. Indicator is set by hardware when EPWM counter down count and reaches EPWM_FTCMPDATn, software can clear this bit by writing 1 to it.
  [8] FTCMD0 — EPWM FTCMPDAT Down Indicator. Indicator is set by hardware when EPWM counter down count and reaches EPWM_FTCMPDATn, software can clear this bit by writing 1 to it.
  [2] FTCMU4 — EPWM FTCMPDAT Up Indicator. Indicator is set by hardware when EPWM counter up count and reaches EPWM_FTCMPDATn, software can clear this bit by writing 1 to it.
  [1] FTCMU2 — EPWM FTCMPDAT Up Indicator. Indicator is set by hardware when EPWM counter up count and reaches EPWM_FTCMPDATn, software can clear this bit by writing 1 to it.
  [0] FTCMU0 — EPWM FTCMPDAT Up Indicator. Indicator is set by hardware when EPWM counter up count and reaches EPWM_FTCMPDATn, software can clear this bit by writing 1 to it.

## EPWM1 — EPWM Register Map
Base 0x40059000
Registers as EPWM0; these are added or differ:
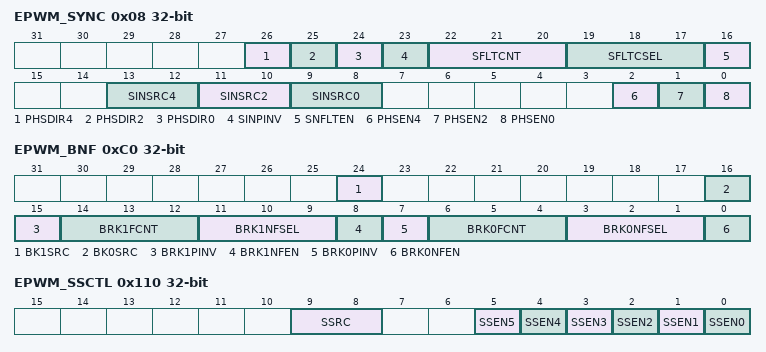
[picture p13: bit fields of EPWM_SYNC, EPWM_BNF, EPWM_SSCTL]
0x08 EPWM_SYNC — EPWM Synchronization Register
  fields as EPWM0.EPWM_SYNC
0xC0 EPWM_BNF — EPWM Brake Noise Filter Register
  fields as EPWM0.EPWM_BNF
0x110 EPWM_SSCTL — EPWM Synchronous Start Control Register
  fields as EPWM0.EPWM_SSCTL
0x114 EPWM_SSTRG wo — EPWM Synchronous Start Trigger Register
  fields as EPWM0.EPWM_SSTRG
